# VPAC0_COMMON_0_IVPAC_TOP_0_CFG_SLV_PAR_VPAC_LDC0_S_VBUSP_MMR_VBUSP register map
Vendor: Texas Instruments
Peripheral module from a debugger description file (folder am62A).
Registers are 32-bit, read-write, reset 0x0 unless marked. A register's access mark holds for its fields unless they carry their own. Offsets are as the file gives them; lines under a group give offsets from that group; [hi:lo] are bit positions; {n}, {i} and the like mark numbered series; 'fields as' and 'values as' point back to an identical list; <NAME> marks a mode.

## VPAC0_COMMON_0_IVPAC_TOP_0_CFG_SLV_PAR_VPAC_LDC0_S_VBUSP_MMR_VBUSP
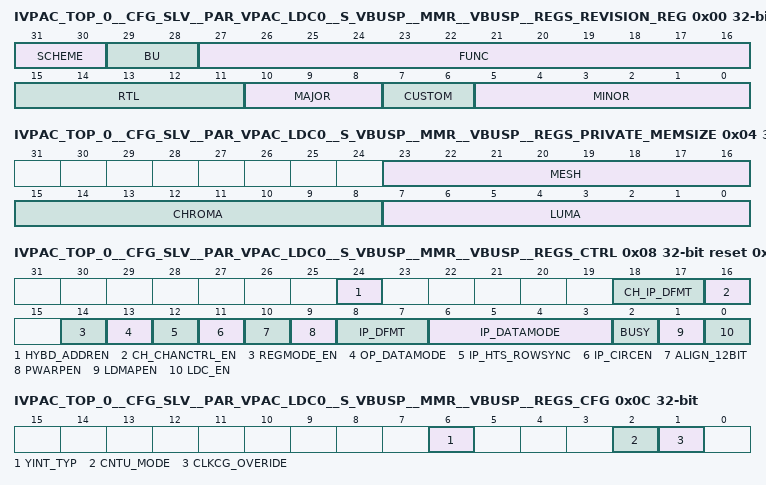
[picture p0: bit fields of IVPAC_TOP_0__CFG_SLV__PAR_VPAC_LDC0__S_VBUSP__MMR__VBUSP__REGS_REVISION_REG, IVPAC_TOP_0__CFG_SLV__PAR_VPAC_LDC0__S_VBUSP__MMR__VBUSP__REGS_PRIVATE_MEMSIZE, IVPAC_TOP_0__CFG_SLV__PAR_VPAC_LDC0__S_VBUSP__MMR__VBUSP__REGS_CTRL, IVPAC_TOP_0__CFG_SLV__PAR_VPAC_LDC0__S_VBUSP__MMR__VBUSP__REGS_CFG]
0x00 IVPAC_TOP_0__CFG_SLV__PAR_VPAC_LDC0__S_VBUSP__MMR__VBUSP__REGS_REVISION_REG ro reset 0x64C60002 — LDC PID
  [31:30] SCHEME — Used to distinguish between old scheme and new scheme. Spare bit to encode future schemes
  [29:28] BU — BU indicator DSPS ==> 0x0 WTBU ==> 0x1 Processors ==> 0x2
  [27:16] FUNC — Function indicates a software compatible module family. If there is no level of software compatibility a new FUNC number, and hence PID, should be assigned.
  [15:11] RTL — RTL Version. R as described in PDR with additional clarifications and definitions below. Must be easily ECO-able or controlled during fabrication. Ideally through a top level metal mask or e-fuse. This number is maintained/owned by IP design owner. RTL follows a numbering such as X.Y.R.Z which are explained in this table. R changes ONLY when: (1) PDS uploads occur which may have been due to spec changes (2) Bug fixes occur (3) Resets to '0' when X or Y changes. Design team has an internal 'Z' (customer invisible) number which increments on every drop that happens due to DV and RTL updates. Z resets to 0 when R increments.
  [10:8] MAJOR — Major Revision. X as described in PDR with additional clarifications/definitions below. This number is owned/maintained by IP specification owner. X is part of IP numbering X.Y.R.Z. X changes ONLY when: (1) There is a major feature addition. An example would be adding Master Mode to Utopia Level2. The Func field (or Class/Type in old PID format) will remain the same. X does NOT change due to: (1) Bug fixes (2) Change in feature parameters.
  [7:6] CUSTOM — Indicates a special version for a particular device. Consequence of use may avoid use of standard Chip Support Library (CSL) / Drivers. 0 if non-custom.
  [5:0] MINOR — Minor Revision. Y as described in PDR with additional clarifications/definitions below. This number is owned/maintained by IP specification owner. Y changes ONLY when: (1) Features are scaled (up or down). Flexibility exists in that this feature scalability may either be represented in the Y change or a specific register in the IP that indicates which features are exactly available. (2) When feature creeps from Is-Not list to Is list. But this may not be the case once it sees silicon - in which case X will change. Y does NOT change due to: (1) Bug fixes (2) Typos or clarifications (3) major functional/feature change/addition/deletion. Instead these changes may be reflected via R, S, X as applicable. Spec owner maintains a customer-invisible number 'S' which changes due to: (1) Typos/clarifications (2) Bug documentation. Note that this bug is not due to a spec change but due to implementation. Nevertheless, the spec tracks the IP bugs. An RTL release (say for silicon PG1.1) that occurs due to bug fix should document the corresponding spec number (X.Y.S) in its release notes.
0x04 IVPAC_TOP_0__CFG_SLV__PAR_VPAC_LDC0__S_VBUSP__MMR__VBUSP__REGS_PRIVATE_MEMSIZE ro reset 0xA2A2A — Memory size mentioned is for both ping and pong combined. Error interrupts are generated based on the memory size available.
  [23:16] MESH — Mesh Private pixel memory size in KBytes
  [15:8] CHROMA — Chroma Private pixel memory size in KBytes
  [7:0] LUMA — Luma Private pixel memory size in KBytes
0x08 IVPAC_TOP_0__CFG_SLV__PAR_VPAC_LDC0__S_VBUSP__MMR__VBUSP__REGS_CTRL access per field reset 0x22090 — Control Register to Enable/Disable and select modes of operation
  [24] HYBD_ADDREN rw — Hybrid addressing scheme Enable. Enabled when part of the data stored in circular buffer and rest in Linear addressing buffers. When enabled, IP_CIRCEN should be high and can only be enabled in frame mode.
  [18:17] CH_IP_DFMT rw — Chroma Input pixel data format. Valid only independent chroma channel control is enbaled (CH_CHANCTRL_EN=1). 0: 8-bit format 1: 12-bit packed format 2: 12-bit unpacked format 3: Reserved
  [16] CH_CHANCTRL_EN rw — Enable for Independent Chroma Channel parameters. Can be enabled only when chroma data is in separate buffer. When enabled, Chroma channel parameters - Input Data Format/Line Offset/Circular buffer size/hybrid addressing parameters should be programmed
  [14] REGMODE_EN rw — Enables for Frame division into multiple regions. Needs to be enabled only when more than one region per frame. 0 - Disable 1 - Enable When enabled, LDC provides option to configure independent block size parameters for each region
  [13] OP_DATAMODE rw — Output Pixel Data Mode; Used when input is YUV422* mode. 0: YUV422 mode 1: convert to YUV420 output data;
  [12] IP_HTS_ROWSYNC rw — Enables control of Input Fetch with HTS at Block Row level. 0 - Disable 1 - Enable When enabled, input fetch of first block in row is gated with corresponding HTS Tstart number. This allows synchronization between VISS and LDC or/and mesh data sync at row level. This can't be enabled when Region mode is enabled
  [11] IP_CIRCEN rw — Enables circular addressing mode on input pixel fetch. Can only be enabled in Frame mode. 0 - Disable circular addressing for input data. 1 - Enable circular addressing.
  [10] ALIGN_12BIT rw — Alignment of 12-bit pixel in 16-bit unpacked data format on input pixel data. Common for both Luma and Chroma channels. 0 - LSB Aligned 1 - MSB Aligned
  [9] PWARPEN rw — Perspective warp transform Enable. Set to 1 to enable use of PWARP_GH.G and PWARP_GH.H
  [8:7] IP_DFMT rw — Input Pixel Data Format 0: 8-bit format 1: 12-bit packed format 2: 12-bit unpacked format 3: Reserved
  [6:3] IP_DATAMODE rw — Input Pixel Data Mode 0: YUV422 UYVY Interleaved data 1: YUV420_Y Luma Data Only 2: YUV420 Data 3: YUV420_UV Chroma Data Only. 4: YUV422_SP Semi-Planar Data. 5: Y1_Y2 - 2 independent channel data at full resolution in separate buffers. 6: Y1_Y2Y3 - 3 independent channel data at full resolution in 2 separate buffers. Y2Y3 data is interleaved. Program frame/block size as in full resolution frame mode
  [2] BUSY ro — Idle/Busy Status, 0: Idle 1: Busy Set on hts_init when LDC_EN is high, cleared on Frame completion
  [1] LDMAPEN rw — Distortion Back Mapping Enable. 1: Enabled 0: Disabled
  [0] LDC_EN rw — Write 1 to enable LDC function. Auto cleared by HW at the end of Frame in OneShoft mode. In continuous mode, needs to cleared by SW at the end to enter Idle condition
0x0C IVPAC_TOP_0__CFG_SLV__PAR_VPAC_LDC0__S_VBUSP__MMR__VBUSP__REGS_CFG — LDC Configuration register. YINT_TYP parameter is used The YINT_TYP parameter only applies to the Y component (Luma). If YINT_TYP = 0, Y pixels are processed using bicubic interpolation, which requires 2 cycles per pixel to process. If YINT_TYP = 1, Y pixels are processed using bilinear interpolation, which requires 1 cycle per pixel to process. This allows a tradeoff between performance versus quality. CbCr (Chroma) pixels are always processed using bilinear interpolation. Thus, the overall performance of pixel processing is based on the Y interpolation type setting. Y1_Y2 & Y1_Y2Y3 modes only bi-linear is allowed.
  [6] YINT_TYP — Interpolation type for Y data. 0: bicubic 1: bilinear
  [2] CNTU_MODE — Continuous mode enable. When enabled, LDC HW won't disable at the end of frame and will start frame processing on hts_init. 0: One Shot mode (default) - LDC enable is cleared at the end of frame 1: Continous mode - LDC will continue to be enabled once set When enabled, LDC_EN needs to be cleared for LDC to go into Idle state
  [1] CLKCG_OVERIDE — Clock gating override control for memory clock gating for Pbist config testing
0x10 IVPAC_TOP_0__CFG_SLV__PAR_VPAC_LDC0__S_VBUSP__MMR__VBUSP__REGS_MESHTABLE_CFG — Defines the down-sampling factors used for the mesh offset tables
  [2:0] M — Mesh table down-sampling factor (by 2^M in both horizontal and Vertical). 0: 1 - no down-sampling 1: 2 - 2x down-sampling 2: 4 3: 8 4: 16 5: 32 6: 64 7:128
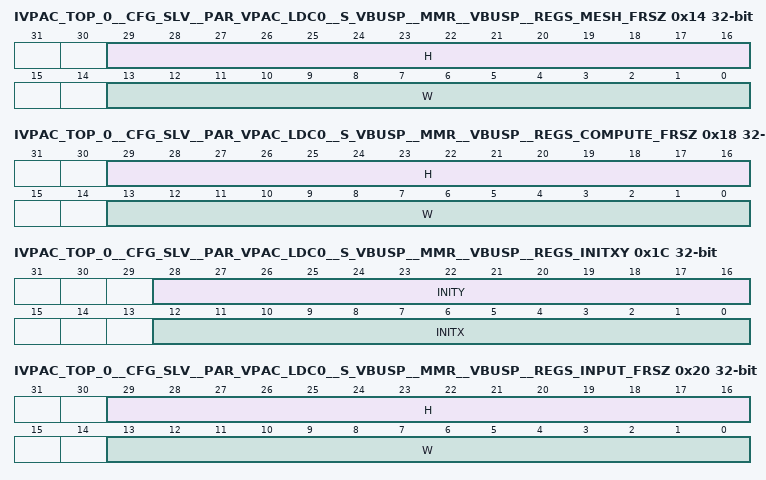
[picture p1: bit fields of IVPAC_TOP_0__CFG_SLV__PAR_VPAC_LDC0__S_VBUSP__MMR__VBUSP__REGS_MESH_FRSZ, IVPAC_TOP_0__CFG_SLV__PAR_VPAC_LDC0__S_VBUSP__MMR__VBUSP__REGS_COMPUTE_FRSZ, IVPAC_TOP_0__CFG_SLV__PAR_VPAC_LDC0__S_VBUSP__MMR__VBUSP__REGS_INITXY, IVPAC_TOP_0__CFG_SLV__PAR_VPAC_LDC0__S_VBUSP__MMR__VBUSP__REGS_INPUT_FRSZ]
0x14 IVPAC_TOP_0__CFG_SLV__PAR_VPAC_LDC0__S_VBUSP__MMR__VBUSP__REGS_MESH_FRSZ — Mesh data mapping is available for this Frame size. Actual number of mesh data entires depend Mesh Frame size and Mesh sampling factor. This Frame size is independent from COMPUTE_FRSZ
  [29:16] H — Mesh Frame height in Lines
  [13:0] W — Mesh Frame Width
0x18 IVPAC_TOP_0__CFG_SLV__PAR_VPAC_LDC0__S_VBUSP__MMR__VBUSP__REGS_COMPUTE_FRSZ — H corresponds to the total number of lines to process. W corresponds to the number of pixels to process in each line. This parameters must be loaded as actual pixel counts, NOT pixel counts - 1. W and H must both be less than or equal to 8192. The hardware does not support output coordinates larger than 8192. Therefore, COMPUTE_FRSZ.W + INITXY.INITX must be no larger than 8192. Also COMPUTE_FRSZ.H + INITXY.INITY must be no larger than 8192.
  [29:16] H — Output Frame height in Lines. Must be even
  [13:0] W — Output Frame Width. Must be even
0x1C IVPAC_TOP_0__CFG_SLV__PAR_VPAC_LDC0__S_VBUSP__MMR__VBUSP__REGS_INITXY — LDC Initial Output Co-ordinate to process
  [28:16] INITY — Output starting Y-coordinate. must be even
  [12:0] INITX — Output starting X-coordinate. must be even
0x20 IVPAC_TOP_0__CFG_SLV__PAR_VPAC_LDC0__S_VBUSP__MMR__VBUSP__REGS_INPUT_FRSZ — Defines the total input frame size
  [29:16] H — Input Frame height in Lines. Must be even
  [13:0] W — Input Frame Width in Pixels. Must be even
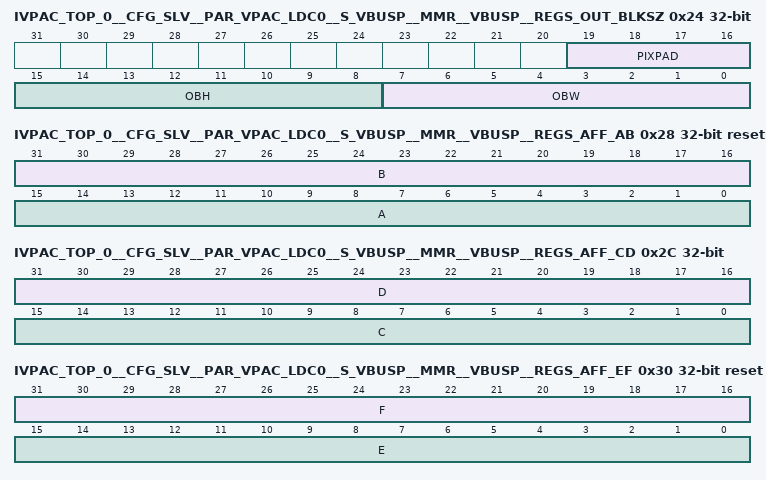
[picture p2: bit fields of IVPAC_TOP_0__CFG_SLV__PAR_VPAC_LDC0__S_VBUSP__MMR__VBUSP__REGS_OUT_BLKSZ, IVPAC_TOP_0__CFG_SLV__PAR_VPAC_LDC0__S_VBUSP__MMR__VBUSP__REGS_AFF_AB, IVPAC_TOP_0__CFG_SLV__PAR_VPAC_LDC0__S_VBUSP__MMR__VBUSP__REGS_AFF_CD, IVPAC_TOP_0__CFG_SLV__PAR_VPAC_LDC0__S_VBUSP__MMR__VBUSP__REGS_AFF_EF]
0x24 IVPAC_TOP_0__CFG_SLV__PAR_VPAC_LDC0__S_VBUSP__MMR__VBUSP__REGS_OUT_BLKSZ — LDC Output Block parameter registers. These parameters represent actual pixel counts, NOT pixel counts - 1. OBW must be greater than 0 and less than or equal to frame width (COMPUTE_FRSZ.W). OBH must be greater than 0 and less than or equal to frame height (COMPUTE_FRSZ.H).
  [19:16] PIXPAD — Pixel pad
  [15:8] OBH — Output block height must be >0 and even
  [7:0] OBW — Output block width, must be >0 and multiple of 8
0x28 IVPAC_TOP_0__CFG_SLV__PAR_VPAC_LDC0__S_VBUSP__MMR__VBUSP__REGS_AFF_AB reset 0x1000 — LDC Affine Transwarp A/B
  [31:16] B — Affine transwarp B (S16Q12)
  [15:0] A — Affine transwarp A (S16Q12)
0x2C IVPAC_TOP_0__CFG_SLV__PAR_VPAC_LDC0__S_VBUSP__MMR__VBUSP__REGS_AFF_CD — LDC Affine Transwarp C/D
  [31:16] D — Affine transwarp D (S16Q12)
  [15:0] C — Affine transwarp C (S16Q3)
0x30 IVPAC_TOP_0__CFG_SLV__PAR_VPAC_LDC0__S_VBUSP__MMR__VBUSP__REGS_AFF_EF reset 0x1000 — LDC Affine Transwarp E/F
  [31:16] F — Affine transwarp F (S16Q3)
  [15:0] E — Affine transwarp E (S16Q12)
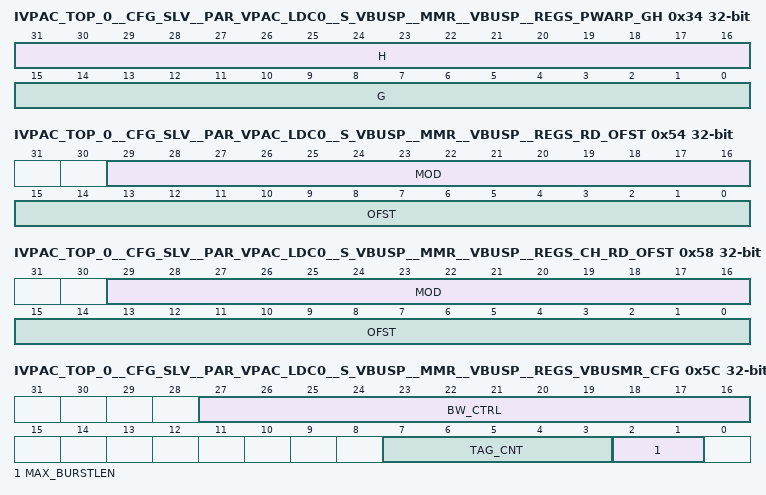
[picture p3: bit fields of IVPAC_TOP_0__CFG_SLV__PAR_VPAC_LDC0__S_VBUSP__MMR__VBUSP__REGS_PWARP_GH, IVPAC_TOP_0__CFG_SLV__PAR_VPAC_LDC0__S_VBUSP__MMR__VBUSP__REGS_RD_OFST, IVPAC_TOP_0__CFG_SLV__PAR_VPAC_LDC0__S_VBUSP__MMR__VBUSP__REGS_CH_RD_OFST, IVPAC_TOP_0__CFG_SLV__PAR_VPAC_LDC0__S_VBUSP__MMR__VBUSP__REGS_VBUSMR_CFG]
0x34 IVPAC_TOP_0__CFG_SLV__PAR_VPAC_LDC0__S_VBUSP__MMR__VBUSP__REGS_PWARP_GH — LDC Perspective Transformation Parameters, G and H
  [31:16] H — Perspective Transformation H (S16Q23)
  [15:0] G — Perspective Transformation H (S16Q23)
0x38 IVPAC_TOP_0__CFG_SLV__PAR_VPAC_LDC0__S_VBUSP__MMR__VBUSP__REGS_MESH_BASE_H — Higher 16-bit of Mesh Table Base Address
  [15:0] ADDR — Higher 16-bit of Read Base address for mesh offset table
0x3C IVPAC_TOP_0__CFG_SLV__PAR_VPAC_LDC0__S_VBUSP__MMR__VBUSP__REGS_MESH_BASE_L — Lower 32-bit of Mesh Table Base Address
  [31:0] ADDR — Lower 32-bit of Read Base address for mesh offset table. Must be 16-byte aligned so four LSB are coded to 0
0x40 IVPAC_TOP_0__CFG_SLV__PAR_VPAC_LDC0__S_VBUSP__MMR__VBUSP__REGS_MESH_OFST — Defines the stride between rows for the Mesh table in bytes.
  [15:0] OFST — LDC Mesh table line offset, must be 16-byte aligned so four LSB are coded to 0
0x44 IVPAC_TOP_0__CFG_SLV__PAR_VPAC_LDC0__S_VBUSP__MMR__VBUSP__REGS_RD_BASE_H — Higher 16-bit of Input Frame Base Address
  [15:0] ADDR
0x48 IVPAC_TOP_0__CFG_SLV__PAR_VPAC_LDC0__S_VBUSP__MMR__VBUSP__REGS_RD_BASE_L — Lower 32-bit of Input Frame Base Address
  [31:0] ADDR — Lower 32-bit of Read Base address of Input Frame Base Address. Must be 16-byte aligned so four LSB are coded to 0
0x4C IVPAC_TOP_0__CFG_SLV__PAR_VPAC_LDC0__S_VBUSP__MMR__VBUSP__REGS_RD_420C_BASE_H — Higher 16-bit of Input Frame 420C Base Address
  [15:0] ADDR — Higher 16-bit of Input Frame Chroma Base Address in YUV420
0x50 IVPAC_TOP_0__CFG_SLV__PAR_VPAC_LDC0__S_VBUSP__MMR__VBUSP__REGS_RD_420C_BASE_L — Lower 32-bit of Input Frame Chroma Base Address in YUV420
  [31:0] ADDR — Lower 32-bit of Read Base address of Input Frame Chroma Base Address in YUV420. Must be 16-byte aligned so four LSB are coded to 0
0x54 IVPAC_TOP_0__CFG_SLV__PAR_VPAC_LDC0__S_VBUSP__MMR__VBUSP__REGS_RD_OFST — Define stride between lines in the Input Frame in bytes and circular buffer height
  [29:16] MOD — Sets the circular buffer size if circular buffering mode is used. The circular buffer is sized in terms of number of lines and has to be multiple of 2
  [15:0] OFST — Read frame line offset, must be 16-byte aligned so internally [3:0] bits are hard-wired zero. OFST is common for Luma and Chroma in YUV420 mode
0x58 IVPAC_TOP_0__CFG_SLV__PAR_VPAC_LDC0__S_VBUSP__MMR__VBUSP__REGS_CH_RD_OFST — Define Chroma stride between lines in the Input Frame in bytes and chroma circular buffer height. Used when CH_CHANCTRL_EN is enabled
  [29:16] MOD — Sets the circular buffer size if circular buffering mode is used. The circular buffer is sized in terms of number of chroma lines
  [15:0] OFST — Read frame line offset, must be 16-byte aligned so internally [3:0] bits are hard-wired zero.
0x5C IVPAC_TOP_0__CFG_SLV__PAR_VPAC_LDC0__S_VBUSP__MMR__VBUSP__REGS_VBUSMR_CFG reset 0xFA — Control VBUSM Read Interface
  [27:16] BW_CTRL — Limits the mean bandwidth (computed over one block) that the LDC module can request for read from system memory. 0: The BW limiter is bypassed 1~4095: maximum number of bytes per 256 cycles. Examples: 1 : 1.17 MBytes/s @ 300 MHz 4095 : ~4.8 GBytes/s @ 300 Mhz
  [7:3] TAG_CNT — Limits the maximum number of outstanding LDC requests to TAG_CNT+1
  [2:1] MAX_BURSTLEN — Limits the maximum burst length that could be used by LDC. Each burst is of 16 bytes. HW also breaks the command at max burst size boundary. For K3 devices, it is best to keep burst size of 8 which command size of 128 bytes. 0: 16 1: 8 2: 4 3: 2
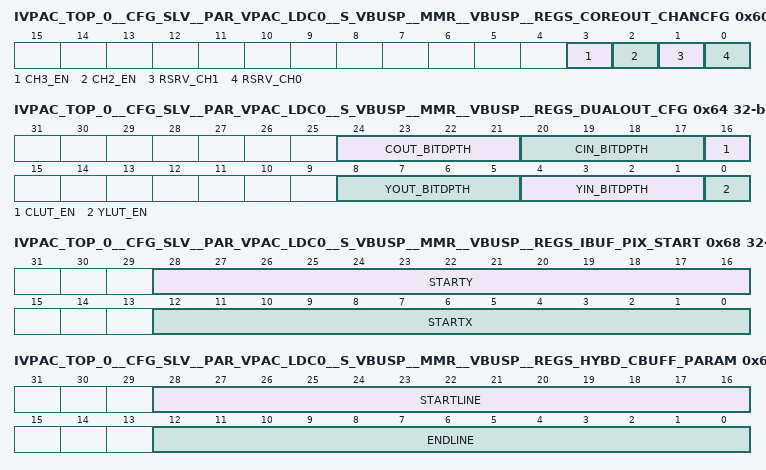
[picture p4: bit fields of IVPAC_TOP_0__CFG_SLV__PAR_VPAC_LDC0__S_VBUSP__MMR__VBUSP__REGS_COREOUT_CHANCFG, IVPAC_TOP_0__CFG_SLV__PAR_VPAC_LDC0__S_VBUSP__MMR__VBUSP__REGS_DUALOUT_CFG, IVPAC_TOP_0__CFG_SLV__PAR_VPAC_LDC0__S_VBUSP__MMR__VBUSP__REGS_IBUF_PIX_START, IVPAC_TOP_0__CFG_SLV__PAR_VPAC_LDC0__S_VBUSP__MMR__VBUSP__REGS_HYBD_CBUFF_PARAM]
0x60 IVPAC_TOP_0__CFG_SLV__PAR_VPAC_LDC0__S_VBUSP__MMR__VBUSP__REGS_COREOUT_CHANCFG access not given — LDC Core to LSE output channel enable control
  [3] CH3_EN rw — Enable for LDC Core to LSE Channel_3 connection used for Chroma Dual output. Expected to be enabled in Y1_Y2Y3 Data mode
  [2] CH2_EN rw — Enable for LDC Core to LSE Channel_2 connection used for Luma Dual output. Should be disabled in Y1_Y2Y3 Data mode
  [1] RSRV_CH1 — Primary Chroma channel (LSE Channel_1) enable extracted from output data mode
  [0] RSRV_CH0 — Primary Luuma channel (LSE Channel_0) enable extracted from output data mode
0x64 IVPAC_TOP_0__CFG_SLV__PAR_VPAC_LDC0__S_VBUSP__MMR__VBUSP__REGS_DUALOUT_CFG reset 0x1180118 — Configuration for Dual Luma and Chroma channels and LUT
  [24:21] COUT_BITDPTH — Chroma Output Data Bit depth. Output clipped at 2^COUT_BITDPTH -1. Valid values 12-8
  [20:17] CIN_BITDPTH — Chroma Input Data Bit depth. Should same as YIN_BITDPTH. Valid values 12 to 8
  [16] CLUT_EN — Chroma LUT mapping enable. If disabled data is sent as it is bypassing LUT mapping. Expected to be disabled in Y1_Y2Y3 Data mode
  [8:5] YOUT_BITDPTH — Luma Output Data Bit depth. Output clipped at 2^YOUT_BITDPTH -1. Valid values 12-8
  [4:1] YIN_BITDPTH — Luma Input Data Bit depth. Valid values 12 to 8
  [0] YLUT_EN — Luma LUT mapping enable. If disabled data is sent as it is bypassing LUT mapping
0x68 IVPAC_TOP_0__CFG_SLV__PAR_VPAC_LDC0__S_VBUSP__MMR__VBUSP__REGS_IBUF_PIX_START — Expected to be used when Circular buffer is enabled. SW needs to make sure that all required pixel data is after this start pixel. Base address and Off Set needs to align with Pixel Start
  [28:16] STARTY — Vertical pixel start position. Must be Even and should be programmed as '0' when hybrid addressing mode is enabled
  [12:0] STARTX — Horizontal pixel start position. Must be align to 16-byte base address
0x6C IVPAC_TOP_0__CFG_SLV__PAR_VPAC_LDC0__S_VBUSP__MMR__VBUSP__REGS_HYBD_CBUFF_PARAM reset 0x1FFF1FFF — Valid when HYBD_ADDREN is enabled. Frame data from Start to end line is stored in Circular buffer and rest of the data in stored in linear buffer(s)
  [28:16] STARTLINE — Start line of the frame which is stored in the circular buffer. Must be even
  [12:0] ENDLINE — End line of the frame which is stored in the circular buffer. Must be Odd
0x70 IVPAC_TOP_0__CFG_SLV__PAR_VPAC_LDC0__S_VBUSP__MMR__VBUSP__REGS_HYBD_CBUFF_BA_H — Higher 16-bit of circular buffer base address in hydrid addressing mode. Valid when HYBD_ADDREN is enabled.
  [15:0] ADDR — Higher 16-bit of circular buffer base address in hydrid addressing mode
0x74 IVPAC_TOP_0__CFG_SLV__PAR_VPAC_LDC0__S_VBUSP__MMR__VBUSP__REGS_HYBD_CBUFF_BA_L — Lower 32-bit of circular buffer base address in hydrid addressing mode. Valid when HYBD_ADDREN is enabled.
  [31:0] ADDR — Lower 32-bit of circular buffer base address in hydrid addressing mode. Must be 16-byte aligned so four LSB are coded to 0
0x78 IVPAC_TOP_0__CFG_SLV__PAR_VPAC_LDC0__S_VBUSP__MMR__VBUSP__REGS_HYBD_BUFF2_BA_H — Higher 16-bit of second linear buffer base address in hydrid addressing mode. Valid when HYBD_ADDREN is enabled.
  [15:0] ADDR — Higher 16-bit of second linear buffer base address in hydrid addressing mode
0x7C IVPAC_TOP_0__CFG_SLV__PAR_VPAC_LDC0__S_VBUSP__MMR__VBUSP__REGS_HYBD_BUFF2_BA_L — Lower 32-bit of second linear buffer base address in hydrid addressing mode. Valid when HYBD_ADDREN is enabled.
  [31:0] ADDR — Lower 32-bit of second linear buffer base address in hydrid addressing mode. Must be 16-byte aligned so four LSB are coded to 0
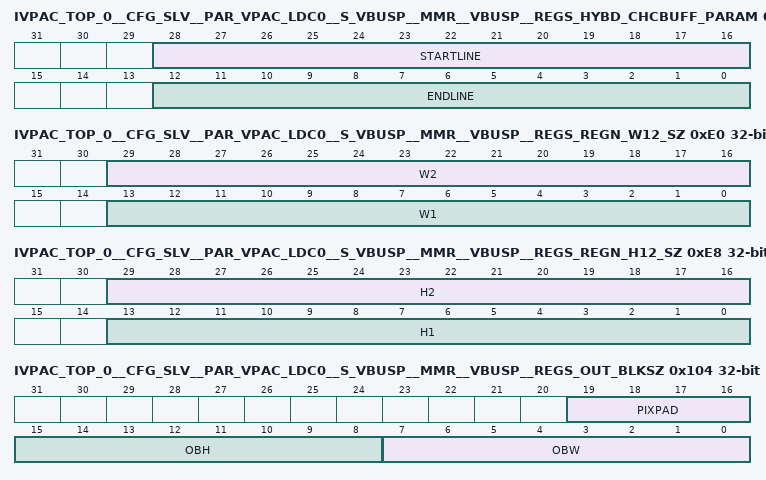
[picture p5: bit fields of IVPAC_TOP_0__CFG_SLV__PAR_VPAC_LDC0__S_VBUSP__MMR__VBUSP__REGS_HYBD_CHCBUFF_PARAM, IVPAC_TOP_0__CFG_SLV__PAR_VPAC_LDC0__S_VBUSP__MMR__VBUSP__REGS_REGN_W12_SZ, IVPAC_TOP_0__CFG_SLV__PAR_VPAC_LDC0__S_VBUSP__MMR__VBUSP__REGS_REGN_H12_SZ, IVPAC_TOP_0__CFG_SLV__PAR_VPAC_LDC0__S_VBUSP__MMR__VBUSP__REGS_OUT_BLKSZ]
0x80 IVPAC_TOP_0__CFG_SLV__PAR_VPAC_LDC0__S_VBUSP__MMR__VBUSP__REGS_HYBD_CHCBUFF_PARAM reset 0x1FFF1FFF — Valid when both CH_CHANCTRL_EN and HYBD_ADDREN are enabled. Frame data from Start to end line is stored in Circular buffer and rest of the data in stored in linear buffers. Program them assuming in full frame lines ; not interms of sub-sampled chroma lines in YUV420 mode
  [28:16] STARTLINE — Start line of the frame which is stored in the circular buffer. Must be even
  [12:0] ENDLINE — End line of the frame which is stored in the circular buffer. Must be odd
0x84 IVPAC_TOP_0__CFG_SLV__PAR_VPAC_LDC0__S_VBUSP__MMR__VBUSP__REGS_HYBD_CHCBUFF_BA_H — Higher 16-bit of chroma circular buffer base address in hydrid addressing mode. Valid when HYBD_ADDREN is enabled.
  fields as IVPAC_TOP_0__CFG_SLV__PAR_VPAC_LDC0__S_VBUSP__MMR__VBUSP__REGS_HYBD_CBUFF_BA_H
0x88 IVPAC_TOP_0__CFG_SLV__PAR_VPAC_LDC0__S_VBUSP__MMR__VBUSP__REGS_HYBD_CHCBUFF_BA_L — Lower 32-bit of chroma circular buffer base address in hydrid addressing mode. Valid when HYBD_ADDREN is enabled.
  fields as IVPAC_TOP_0__CFG_SLV__PAR_VPAC_LDC0__S_VBUSP__MMR__VBUSP__REGS_HYBD_CBUFF_BA_L
0x8C IVPAC_TOP_0__CFG_SLV__PAR_VPAC_LDC0__S_VBUSP__MMR__VBUSP__REGS_HYBD_CHBUFF2_BA_H — Higher 16-bit of second linear chroma buffer base address in hydrid addressing mode. Valid when HYBD_ADDREN is enabled.
  fields as IVPAC_TOP_0__CFG_SLV__PAR_VPAC_LDC0__S_VBUSP__MMR__VBUSP__REGS_HYBD_BUFF2_BA_H
0x90 IVPAC_TOP_0__CFG_SLV__PAR_VPAC_LDC0__S_VBUSP__MMR__VBUSP__REGS_HYBD_CHBUFF2_BA_L — Lower 32-bit of second linear chroma buffer base address in hydrid addressing mode. Valid when HYBD_ADDREN is enabled.
  fields as IVPAC_TOP_0__CFG_SLV__PAR_VPAC_LDC0__S_VBUSP__MMR__VBUSP__REGS_HYBD_BUFF2_BA_L
0xE0 IVPAC_TOP_0__CFG_SLV__PAR_VPAC_LDC0__S_VBUSP__MMR__VBUSP__REGS_REGN_W12_SZ — Horizontal slice width for Region division
  [29:16] W2 — Width of second horizontal slice. (Minimum of 8 and must be even)
  [13:0] W1 — Width of first horizontal slice. (Minimum of 8 and must be even)
0xE4 IVPAC_TOP_0__CFG_SLV__PAR_VPAC_LDC0__S_VBUSP__MMR__VBUSP__REGS_REGN_W3_SZ — Horizontal slice width for Region division
  [13:0] W3 — Width of third horizontal slice. (Minimum of 8 and must be even)
0xE8 IVPAC_TOP_0__CFG_SLV__PAR_VPAC_LDC0__S_VBUSP__MMR__VBUSP__REGS_REGN_H12_SZ — vertical slice height for Region division
  [29:16] H2 — Height of second vertical slice. (must be even)
  [13:0] H1 — Height of first vertical slice. (must be even)
0xEC IVPAC_TOP_0__CFG_SLV__PAR_VPAC_LDC0__S_VBUSP__MMR__VBUSP__REGS_REGN_H3_SZ — Vertical slice height for Region division
  [13:0] H3 — Height of third vertical slice. (must be even)
0x100 IVPAC_TOP_0__CFG_SLV__PAR_VPAC_LDC0__S_VBUSP__MMR__VBUSP__REGS_CTRL reset 0x1 — Region Control Register
  [0] ENABLE — Enable for processing of this region. This is can be used to selectively disable processing of some regions (default enabled). 1 - Process the region i.e. no skipping 0 - Don't process the region
0x104 IVPAC_TOP_0__CFG_SLV__PAR_VPAC_LDC0__S_VBUSP__MMR__VBUSP__REGS_OUT_BLKSZ — Block size and Pixel Pad config
  [19:16] PIXPAD — Pixel pad
  [15:8] OBH — Output block height must be >0 and even. Should be less than or equal to corresponding region height
  [7:0] OBW — Output block width, must be >0 and multiple of 8. Should be less than or equal to corresponding region width
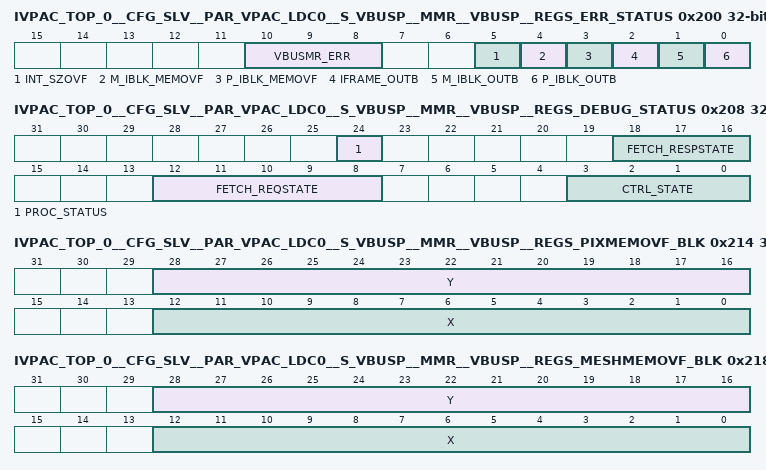
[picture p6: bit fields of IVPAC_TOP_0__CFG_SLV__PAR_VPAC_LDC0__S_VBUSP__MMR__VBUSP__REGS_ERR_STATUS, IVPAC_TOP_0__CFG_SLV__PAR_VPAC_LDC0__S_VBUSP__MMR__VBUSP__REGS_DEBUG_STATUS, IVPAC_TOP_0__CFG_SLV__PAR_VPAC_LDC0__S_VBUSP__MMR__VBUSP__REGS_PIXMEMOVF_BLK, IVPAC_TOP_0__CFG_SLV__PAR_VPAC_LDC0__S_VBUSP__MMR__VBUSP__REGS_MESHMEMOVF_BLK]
0x200 IVPAC_TOP_0__CFG_SLV__PAR_VPAC_LDC0__S_VBUSP__MMR__VBUSP__REGS_ERR_STATUS access not given — Control VBUSM Read Interface
  [10:8] VBUSMR_ERR — VBUSM Read I/F Last Error Status. Write '1' to clear, works independently for each bit. (access R/W1TC)
  [5] INT_SZOVF — Internal operation has overflown the HW supported block or frame sizes. Should be fixed (access R/W1TC)
  [4] M_IBLK_MEMOVF — Mesh block storage requirement is more than internal memory available. Should be fixed (access R/W1TC)
  [3] P_IBLK_MEMOVF — Input pixel block storage requirement is more than internal memory available. Should be fixed (access R/W1TC)
  [2] IFRAME_OUTB — Either Mesh data or Input pixel data required is going out of valid frame available (access R/W1TC)
  [1] M_IBLK_OUTB — Mesh Input Block out of Bound. Mesh data required for block is not available in the prefetched internal memory. Should be fine. (access R/W1TC)
  [0] P_IBLK_OUTB — Pixel Input Block out of Bound. Pixel data required for block is not available in the prefetched internal memory. PIX_PAD is not enough (access R/W1TC)
0x204 IVPAC_TOP_0__CFG_SLV__PAR_VPAC_LDC0__S_VBUSP__MMR__VBUSP__REGS_DEBUG_CTRL — Control the memory access selection
  [0] CFG_MEMACC_SEL — VBUSP Configuration access control. 0 - VBUSP can access Ping memories 1 - VBUSP can access pong memories All private memories Mesh,Luma, Chroma will share same control. Ping and pong memories will have same memory map
0x208 IVPAC_TOP_0__CFG_SLV__PAR_VPAC_LDC0__S_VBUSP__MMR__VBUSP__REGS_DEBUG_STATUS ro reset 0x1000000 — LDC Debug Status Register
  [24] PROC_STATUS — Block Processing status. 0 - Block Processing is ongoing 1 - Either block processing is completed or not started
  [18:16] FETCH_RESPSTATE — VBUSM Fetch Response state machine 3'd0 = ST_RESP_IDLE 3'd1 = ST_RESP_MREQWAIT 3'd2 = ST_RESP_MRESPWAIT 3'd3 = ST_RESP_IREQWAIT 3'd4 = ST_RESP_IRESPWAIT 3'd5 = ST_RESP_DONE
  [12:8] FETCH_REQSTATE — VBUSM Fetch Request state machine 5'b00_000 = ST_REQ_IDLE 5'b10_000 = ST_REQ_MBASECAL 5'b10_001 = ST_REQ_MDATA 5'b11_000 = ST_REQ_INITWAIT 5'b11_001 = ST_REQ_ICBUF 5'b11_010 = ST_REQ_IBASECAL 5'b11_011 = ST_REQ_IDATA
  [3:0] CTRL_STATE — Main Control State machine 4'd0 = STATE_IDLE 4'd1 = STATE_GET_BLOCK_P1 4'd2 = STATE_GET_BLOCK_P2 4'd3 = STATE_GET_BLOCK_P3 4'd4 = STATE_GET_BLOCK_P4 4'd5 = STATE_SET_BLOCK_PWARP 4'd6 = STATE_SET_BLOCK_MESHDC 4'd7 = STATE_INIT_BLOCK 4'd8 = STATE_GET_BLOCK 4'd9 = STATE_WAIT_PROCESS_DONE 4'd10 = STATE_LAST_PROCESS 4'd11 = STATE_LAST_PROCESS_DONE
0x20C IVPAC_TOP_0__CFG_SLV__PAR_VPAC_LDC0__S_VBUSP__MMR__VBUSP__REGS_FR_PDFTCH ro — Pixel bytes fetched by VBUSM Read Interface. It is updated on every command issued and cleared at the beginning frame fetch. Reading at the end of the frame will provide total number of pixel data fetched for entire frame
  [31:0] PBYTES — Pixel bytes fetched for current Frame. Reading at the end of frame will provide pixel data fetched for entire frame
0x210 IVPAC_TOP_0__CFG_SLV__PAR_VPAC_LDC0__S_VBUSP__MMR__VBUSP__REGS_FR_MDFTCH ro — Mesh bytes fetched by VBUSM Read Interface. It is updated on every command issued and cleared at the beginning frame fetch. Reading at the end of the frame will provide total number of mesh data band fetched for entire frame
  [31:0] MBYTES — Mesh bytes fetched for current Frame. Reading at the end of frame will provide Mesh data fetched for entire frame
0x214 IVPAC_TOP_0__CFG_SLV__PAR_VPAC_LDC0__S_VBUSP__MMR__VBUSP__REGS_PIXMEMOVF_BLK ro — Starting co-ordinates of first output block for which input pixel buffer overflowed
  [28:16] Y — Start Y Co-ordinate
  [12:0] X — Start X Co-ordinate
0x218 IVPAC_TOP_0__CFG_SLV__PAR_VPAC_LDC0__S_VBUSP__MMR__VBUSP__REGS_MESHMEMOVF_BLK ro — Starting co-ordinates of first output block for which input mesh buffer overflowed
  [28:16] Y — Start Y Co-ordinate
  [12:0] X — Start X Co-ordinate
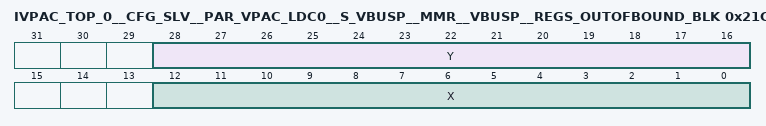
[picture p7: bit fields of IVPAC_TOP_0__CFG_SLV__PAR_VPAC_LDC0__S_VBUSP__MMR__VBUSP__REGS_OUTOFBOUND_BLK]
0x21C IVPAC_TOP_0__CFG_SLV__PAR_VPAC_LDC0__S_VBUSP__MMR__VBUSP__REGS_OUTOFBOUND_BLK ro — Starting co-ordinates of first output block for which PIX_PAD is not enough
  [28:16] Y — Start Y Co-ordinate
  [12:0] X — Start X Co-ordinate
